# ESP32-S2 register map
Vendor: ESPRESSIF SYSTEMS (SHANGHAI) CO., LTD.; Series: ESP32 S-Series; File version: 20
CPU: Xtensa LX7 r0p0, little endian, no MPU, no FPU, 0 interrupt priority bits
Address unit: 32 bits
Registers are 32-bit, read-write, reset 0x0 unless marked. A register's access mark holds for its fields unless they carry their own. Offsets are from the block's base; [hi:lo] are bit positions; {n}, {i} and the like mark numbered series.

## RTC_I2C — Low-power I2C (Inter-Integrated Circuit) Controller
Base 0x3F408C00
0x00 SCL_LOW reset 0x100 — Configure the low level width of SCL
  [19:0] PERIOD — This register is used to configure how many clock cycles SCL remains low.
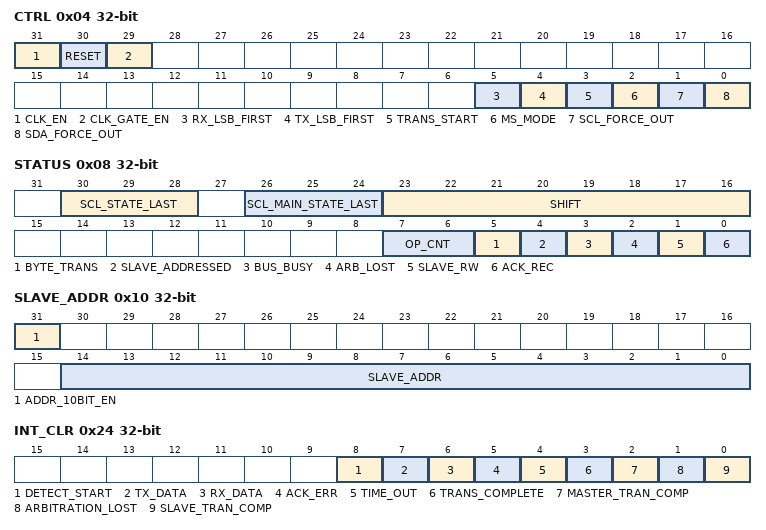
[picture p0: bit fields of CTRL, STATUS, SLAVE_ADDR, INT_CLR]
0x04 CTRL — Transmission setting
  [31] CLK_EN — rtc i2c reg clk gating
  [30] RESET — RTC I²C software reset.
  [29] CLK_GATE_EN — RTC I²C controller clock gate.
  [5] RX_LSB_FIRST — This bit is used to control the storage mode for received data. 0: receive data from the most significant bit. 1: receive data from the least significant bit.
  [4] TX_LSB_FIRST — This bit is used to control the sending mode. 0: send data from the most significant bit. 1: send data from the least significant bit.
  [3] TRANS_START — Set this bit to 1, RTC I2C starts sending data.
  [2] MS_MODE — Set this bit to configure RTC I²C as a master.
  [1] SCL_FORCE_OUT — SCL output mode. 0: open drain. 1: push pull.
  [0] SDA_FORCE_OUT — SDA output mode. 0: open drain. 1: push pull.
0x08 STATUS ro — RTC I2C status
  [30:28] SCL_STATE_LAST — scl last status
  [26:24] SCL_MAIN_STATE_LAST — i2c last main status
  [23:16] SHIFT — shifter content
  [7:6] OP_CNT — Indicate which operation is working.
  [5] BYTE_TRANS — This field changes to 1 when one byte is transferred.
  [4] SLAVE_ADDRESSED — When the address sent by the master matches the address of the slave, then this bit will be set.
  [3] BUS_BUSY — 0: RTC I2C bus is in idle state. 1: RTC I2C bus is busy transferring data.
  [2] ARB_LOST — When the RTC I2C loses control of SCL line, the register changes to 1.
  [1] SLAVE_RW — 0: master writes to slave. 1: master reads from slave.
  [0] ACK_REC — The received ACK value. 0: ACK. 1: NACK.
0x0C TO reset 0x10000 — Configure RTC I2C timeout
  [19:0] TIME_OUT — Timeout threshold
0x10 SLAVE_ADDR — Configure slave address
  [31] ADDR_10BIT_EN — This field is used to enable the slave 10-bit addressing mode.
  [14:0] SLAVE_ADDR — slave address
0x14 SCL_HIGH reset 0x100 — Configure the high level width of SCL
  [19:0] PERIOD — This register is used to configure how many cycles SCL remains high.
0x18 SDA_DUTY reset 0x10 — Configure the SDA hold time after a negative SCL edge
  [19:0] NUM — The number of clock cycles between the SDA switch and the falling edge of SCL.
0x1C SCL_START_PERIOD reset 0x8 — Configure the delay between the SDA and SCL negative edge for a start condition
  [19:0] SCL_START_PERIOD — Number of clock cycles to wait after generating a start condition.
0x20 SCL_STOP_PERIOD reset 0x8 — Configure the delay between SDA and SCL positive edge for a stop condition
  [19:0] SCL_STOP_PERIOD — Number of clock cycles to wait before generating a stop condition.
0x24 INT_CLR wo — Clear RTC I2C interrupt
  [8] DETECT_START write-1-clears — RTC_I2C_DETECT_START_INT interrupt clear bit
  [7] TX_DATA write-1-clears — RTC_I2C_TX_DATA_INT interrupt clear bit
  [6] RX_DATA write-1-clears — RTC_I2C_RX_DATA_INT interrupt clear bit
  [5] ACK_ERR write-1-clears — RTC_I2C_ACK_ERR_INT interrupt clear bit
  [4] TIME_OUT write-1-clears — RTC_I2C_TIME_OUT_INT interrupt clear bit
  [3] TRANS_COMPLETE write-1-clears — RTC_I2C_TRANS_COMPLETE_INT interrupt clear bit
  [2] MASTER_TRAN_COMP write-1-clears — RTC_I2C_MASTER_TRAN_COMP_INT interrupt clear bit
  [1] ARBITRATION_LOST write-1-clears — RTC_I2C_ARBITRATION_LOST_INT interrupt clear bit
  [0] SLAVE_TRAN_COMP write-1-clears — RTC_I2C_SLAVE_TRAN_COMP_INT interrupt clear bit
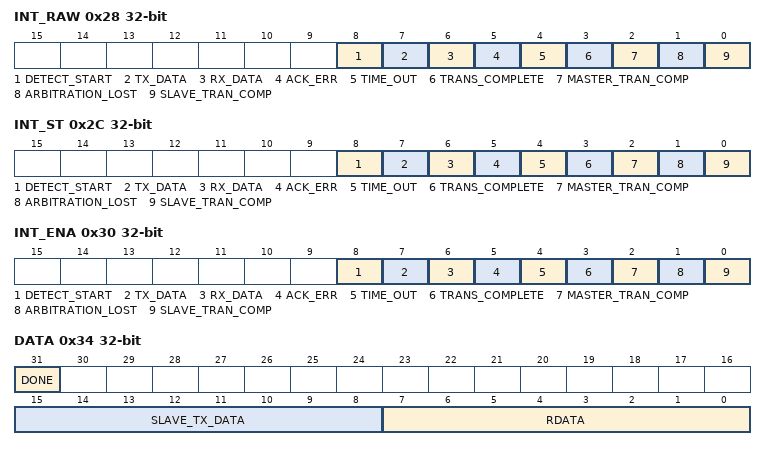
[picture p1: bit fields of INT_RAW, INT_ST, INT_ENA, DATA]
0x28 INT_RAW ro — RTC I2C raw interrupt
  [8] DETECT_START — RTC_I2C_DETECT_START_INT interrupt raw bit
  [7] TX_DATA — RTC_I2C_TX_DATA_INT interrupt raw bit
  [6] RX_DATA — RTC_I2C_RX_DATA_INT interrupt raw bit
  [5] ACK_ERR — RTC_I2C_ACK_ERR_INT interrupt raw bit
  [4] TIME_OUT — RTC_I2C_TIME_OUT_INT interrupt raw bit
  [3] TRANS_COMPLETE — RTC_I2C_TRANS_COMPLETE_INT interrupt raw bit
  [2] MASTER_TRAN_COMP — RTC_I2C_MASTER_TRAN_COMP_INT interrupt raw bit
  [1] ARBITRATION_LOST — RTC_I2C_ARBITRATION_LOST_INT interrupt raw bit
  [0] SLAVE_TRAN_COMP — RTC_I2C_SLAVE_TRAN_COMP_INT interrupt raw bit
0x2C INT_ST ro — RTC I2C interrupt status
  [8] DETECT_START — RTC_I2C_DETECT_START_INT interrupt status bit
  [7] TX_DATA — RTC_I2C_TX_DATA_INT interrupt status bit
  [6] RX_DATA — RTC_I2C_RX_DATA_INT interrupt status bit
  [5] ACK_ERR — RTC_I2C_ACK_ERR_INT interrupt status bit
  [4] TIME_OUT — RTC_I2C_TIME_OUT_INT interrupt status bit
  [3] TRANS_COMPLETE — RTC_I2C_TRANS_COMPLETE_INT interrupt status bit
  [2] MASTER_TRAN_COMP — RTC_I2C_MASTER_TRAN_COMP_INT interrupt status bit
  [1] ARBITRATION_LOST — RTC_I2C_ARBITRATION_LOST_INT interrupt status bit
  [0] SLAVE_TRAN_COMP — RTC_I2C_SLAVE_TRAN_COMP_INT interrupt status bit
0x30 INT_ENA — Enable RTC I2C interrupt
  [8] DETECT_START — RTC_I2C_DETECT_START_INT interrupt enable bit
  [7] TX_DATA — RTC_I2C_TX_DATA_INT interrupt enable bit
  [6] RX_DATA — RTC_I2C_RX_DATA_INT interrupt enable bit
  [5] ACK_ERR — RTC_I2C_ACK_ERR_INT interrupt enable bit
  [4] TIME_OUT — RTC_I2C_TIME_OUT_INT interrupt enable bit
  [3] TRANS_COMPLETE — RTC_I2C_TRANS_COMPLETE_INT interrupt enable bit
  [2] MASTER_TRAN_COMP — RTC_I2C_MASTER_TRAN_COMP_INT interrupt enable bit
  [1] ARBITRATION_LOST — RTC_I2C_ARBITRATION_LOST_INT interrupt enable bit
  [0] SLAVE_TRAN_COMP — RTC_I2C_SLAVE_TRAN_COMP_INT interrupt enable bit
0x34 DATA access per field — RTC I2C read data
  [31] DONE ro — RTC I2C transmission is done.
  [15:8] SLAVE_TX_DATA rw — The data sent by slave
  [7:0] RDATA ro — Data received
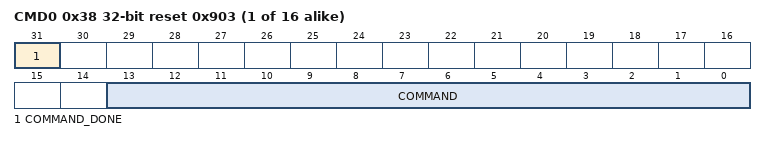
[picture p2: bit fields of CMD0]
{0x38+4i} CMD{i} (i=0..15) access per field reset 0x903 — RTC I2C Command {i}
  [31] COMMAND_DONE ro — When command 0 is done, this bit changes to 1.
  [13:0] COMMAND rw — Content of command 0. For more information, please refer to the register I2C_COMD0_REG in Chapter I²C Controller
0xFC DATE — Version control register
